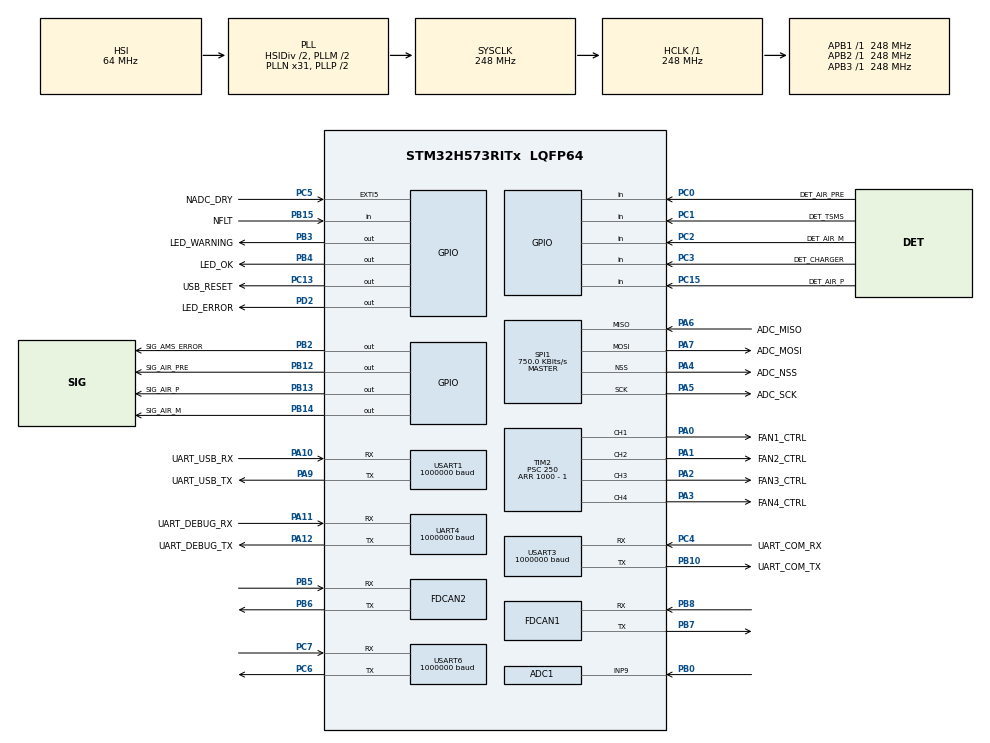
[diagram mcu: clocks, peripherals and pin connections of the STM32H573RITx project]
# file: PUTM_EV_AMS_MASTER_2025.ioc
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ADC1.Channel-0\#ChannelRegularConversion=ADC_CHANNEL_9
ADC1.ClockPrescaler=ADC_CLOCK_ASYNC_DIV16
ADC1.ContinuousConvMode=ENABLE
ADC1.MonitoredBy-0\#ChannelRegularConversion=__NULL
ADC1.NbrOfConversionFlag=1
ADC1.OffsetNumber-0\#ChannelRegularConversion=ADC_OFFSET_NONE
ADC1.Overrun=ADC_OVR_DATA_OVERWRITTEN
ADC1.Rank-0\#ChannelRegularConversion=1
ADC1.SamplingTime-0\#ChannelRegularConversion=ADC_SAMPLETIME_640CYCLES_5
ADC1.master=1
BOOTPATH.BootPathName=LEGACY
BOOTPATH.UserSelectedBootPath=LEGACY
CORTEX_M33_NS.userName=CORTEX_M33
FDCAN1.CalculateBaudRateNominal=500000
FDCAN1.CalculateTimeBitNominal=2000
FDCAN1.CalculateTimeQuantumNominal=32.25806451612903
FDCAN1.ClockDivider=FDCAN_CLOCK_DIV4
FDCAN1.DataPrescaler=8
FDCAN1.DataSyncJumpWidth=15
FDCAN1.DataTimeSeg1=15
FDCAN1.DataTimeSeg2=15
FDCAN1.Mode=FDCAN_MODE_NORMAL
FDCAN1.NominalPrescaler=2
FDCAN1.NominalSyncJumpWidth=2
FDCAN1.NominalTimeSeg1=59
FDCAN1.NominalTimeSeg2=2
FDCAN1.StdFiltersNbr=0
FDCAN2.CalculateBaudRateNominal=1000000
FDCAN2.CalculateTimeBitNominal=1000
FDCAN2.CalculateTimeQuantumNominal=16.129032258064516
FDCAN2.ClockDivider=FDCAN_CLOCK_DIV4
FDCAN2.DataPrescaler=2
FDCAN2.DataSyncJumpWidth=15
FDCAN2.DataTimeSeg1=15
FDCAN2.DataTimeSeg2=15
FDCAN2.Mode=FDCAN_MODE_NORMAL
FDCAN2.NominalPrescaler=1
FDCAN2.NominalSyncJumpWidth=15
FDCAN2.NominalTimeSeg1=46
FDCAN2.NominalTimeSeg2=15
FLASH.EDATA2size=7
FLASH.OB_EDATA2_active=true
FLASH.advanced_settings=false
GPDMA1.DATAHANDLING_GPDMACH2=NONE
GPDMA1.DESTDATAWIDTH_GPDMACH0=DMA_DEST_DATAWIDTH_WORD
GPDMA1.DESTDATAWIDTH_GPDMACH1=DMA_DEST_DATAWIDTH_WORD
GPDMA1.DESTINC_GPDMACH0=DMA_DINC_INCREMENTED
GPDMA1.DESTINC_GPDMACH2=DMA_DINC_INCREMENTED
GPDMA1.DESTINC_GPDMACH3=DMA_DINC_FIXED
GPDMA1.DIRECTION_GPDMACH1=DMA_MEMORY_TO_PERIPH
GPDMA1.DIRECTION_GPDMACH3=DMA_MEMORY_TO_PERIPH
GPDMA1.DIRECTION_GPDMACH4=DMA_MEMORY_TO_PERIPH
GPDMA1.IPHANDLE_GPDMACH0-SIMPLEREQUEST_GPDMACH0=__NULL
GPDMA1.IPHANDLE_GPDMACH1-SIMPLEREQUEST_GPDMACH1=__NULL
GPDMA1.IPHANDLE_GPDMACH2-SIMPLEREQUEST_GPDMACH2=__NULL
GPDMA1.IPHANDLE_GPDMACH3-SIMPLEREQUEST_GPDMACH3=__NULL
GPDMA1.IPHANDLE_GPDMACH4-SIMPLEREQUEST_GPDMACH4=__NULL
GPDMA1.REQUEST_GPDMACH0=GPDMA1_REQUEST_SPI1_RX
GPDMA1.REQUEST_GPDMACH1=GPDMA1_REQUEST_SPI1_TX
GPDMA1.REQUEST_GPDMACH2=GPDMA1_REQUEST_UART4_RX
GPDMA1.REQUEST_GPDMACH3=GPDMA1_REQUEST_UART4_TX
GPDMA1.REQUEST_GPDMACH4=GPDMA1_REQUEST_USART6_TX
GPDMA1.SRCDATAWIDTH_GPDMACH0=DMA_SRC_DATAWIDTH_WORD
GPDMA1.SRCDATAWIDTH_GPDMACH1=DMA_SRC_DATAWIDTH_WORD
GPDMA1.SRCINC_GPDMACH0=DMA_SINC_FIXED
GPDMA1.SRCINC_GPDMACH1=DMA_SINC_INCREMENTED
GPDMA1.SRCINC_GPDMACH3=DMA_SINC_INCREMENTED
GPDMA1.TRANSFERALLOCATEDPORTDEST_GPDMACH0=DMA_DEST_ALLOCATED_PORT1
GPDMA1.TRANSFERALLOCATEDPORTDEST_GPDMACH1=DMA_DEST_ALLOCATED_PORT0
GPDMA1.TRANSFERALLOCATEDPORTDEST_GPDMACH2=DMA_DEST_ALLOCATED_PORT1
GPDMA1.TRANSFERALLOCATEDPORTSRC_GPDMACH1=DMA_SRC_ALLOCATED_PORT1
GPDMA1.TRANSFERALLOCATEDPORTSRC_GPDMACH3=DMA_SRC_ALLOCATED_PORT1
GPDMA1.TRIGGERPOLARITY_GPDMACH2=DMA_TRIG_POLARITY_MASKED
GPDMA2.DESTINC_GPDMACH0=DMA_DINC_INCREMENTED
GPDMA2.DESTINC_GPDMACH2=DMA_DINC_INCREMENTED
GPDMA2.DIRECTION_GPDMACH1=DMA_MEMORY_TO_PERIPH
GPDMA2.DIRECTION_GPDMACH3=DMA_MEMORY_TO_PERIPH
GPDMA2.IPHANDLE_GPDMACH0-SIMPLEREQUEST_GPDMACH0=__NULL
GPDMA2.IPHANDLE_GPDMACH1-SIMPLEREQUEST_GPDMACH1=__NULL
GPDMA2.IPHANDLE_GPDMACH2-SIMPLEREQUEST_GPDMACH2=__NULL
GPDMA2.IPHANDLE_GPDMACH3-SIMPLEREQUEST_GPDMACH3=__NULL
GPDMA2.REQUEST_GPDMACH0=GPDMA2_REQUEST_USART1_RX
GPDMA2.REQUEST_GPDMACH1=GPDMA2_REQUEST_USART1_TX
GPDMA2.REQUEST_GPDMACH2=GPDMA2_REQUEST_USART3_RX
GPDMA2.REQUEST_GPDMACH3=GPDMA2_REQUEST_USART3_TX
GPDMA2.SRCINC_GPDMACH1=DMA_SINC_INCREMENTED
GPDMA2.SRCINC_GPDMACH3=DMA_SINC_INCREMENTED
GPDMA2.TRANSFERALLOCATEDPORTDEST_GPDMACH0=DMA_DEST_ALLOCATED_PORT1
GPDMA2.TRANSFERALLOCATEDPORTDEST_GPDMACH2=DMA_DEST_ALLOCATED_PORT1
GPDMA2.TRANSFERALLOCATEDPORTSRC_GPDMACH1=DMA_SRC_ALLOCATED_PORT1
GPDMA2.TRANSFERALLOCATEDPORTSRC_GPDMACH3=DMA_SRC_ALLOCATED_PORT1
Mcu.Family=STM32H5
Mcu.Name=STM32H573RITx
Mcu.Package=LQFP64
NVIC.FDCAN2_IT0_IRQn=true\:0\:0\:false\:false\:true\:false\:true\:true\:true
NVIC.FDCAN2_IT1_IRQn=true\:0\:0\:false\:false\:true\:false\:true\:true\:true
NVIC.GPDMA1_Channel0_IRQn=true\:0\:0\:false\:false\:true\:false\:true\:true\:true
NVIC.GPDMA1_Channel1_IRQn=true\:0\:0\:false\:false\:true\:false\:true\:true\:true
NVIC.GPDMA1_Channel2_IRQn=true\:0\:0\:false\:false\:true\:false\:false\:true\:true
NVIC.GPDMA1_Channel3_IRQn=true\:0\:0\:false\:false\:true\:false\:false\:true\:true
NVIC.GPDMA1_Channel4_IRQn=true\:0\:0\:false\:false\:true\:true\:false\:true\:true
NVIC.GPDMA2_Channel0_IRQn=true\:0\:0\:false\:false\:true\:true\:false\:true\:true
NVIC.GPDMA2_Channel1_IRQn=true\:0\:0\:false\:false\:true\:true\:false\:true\:true
NVIC.GPDMA2_Channel2_IRQn=true\:0\:0\:false\:false\:true\:true\:false\:true\:true
NVIC.GPDMA2_Channel3_IRQn=true\:0\:0\:false\:false\:true\:true\:false\:true\:true
NVIC.PriorityGroup=NVIC_PRIORITYGROUP_4
NVIC.SPI1_IRQn=true\:0\:0\:false\:false\:true\:false\:true\:true\:true
NVIC.TIM1_UP_IRQn=true\:15\:0\:false\:false\:true\:false\:false\:true\:true
NVIC.TimeBase=TIM1_UP_IRQn
NVIC.TimeBaseIP=TIM1
NVIC.UART4_IRQn=true\:0\:0\:false\:false\:true\:false\:true\:true\:true
NVIC.USART1_IRQn=true\:0\:0\:false\:false\:true\:false\:true\:true\:true
NVIC.USART3_IRQn=true\:0\:0\:false\:false\:true\:false\:true\:true\:true
NVIC.USART6_IRQn=true\:0\:0\:false\:false\:true\:false\:true\:true\:true
PA0.GPIO_Label=FAN1_CTRL
PA0.Signal=S_TIM2_CH1
PA1.GPIO_Label=FAN2_CTRL
PA1.Signal=S_TIM2_CH2
PA10.GPIO_Label=UART_USB_RX
PA10.Mode=Asynchronous
PA10.Signal=USART1_RX
PA11.GPIO_Label=UART_DEBUG_RX
PA11.Mode=Asynchronous
PA11.Signal=UART4_RX
PA12.GPIO_Label=UART_DEBUG_TX
PA12.Mode=Asynchronous
PA12.Signal=UART4_TX
PA13(JTMS/SWDIO).Mode=Serial_Wire
PA13(JTMS/SWDIO).Signal=DEBUG_JTMS-SWDIO
PA14(JTCK/SWCLK).Mode=Serial_Wire
PA14(JTCK/SWCLK).Signal=DEBUG_JTCK-SWCLK
PA2.GPIO_Label=FAN3_CTRL
PA2.Signal=S_TIM2_CH3
PA3.GPIO_Label=FAN4_CTRL
PA3.Signal=S_TIM2_CH4
PA4.GPIO_Label=ADC_NSS
PA4.Mode=NSS_Signal_Hard_Output
PA4.Signal=SPI1_NSS
PA5.GPIO_Label=ADC_SCK
PA5.Mode=Full_Duplex_Master
PA5.Signal=SPI1_SCK
PA6.GPIO_Label=ADC_MISO
PA6.Mode=Full_Duplex_Master
PA6.Signal=SPI1_MISO
PA7.GPIO_Label=ADC_MOSI
PA7.Mode=Full_Duplex_Master
PA7.Signal=SPI1_MOSI
PA9.GPIO_Label=UART_USB_TX
PA9.Mode=Asynchronous
PA9.Signal=USART1_TX
PB0.Signal=ADCx_INP9
PB10.GPIO_Label=UART_COM_TX
PB10.Mode=Asynchronous
PB10.Signal=USART3_TX
PB12.GPIO_Label=SIG_AIR_PRE
PB12.Signal=GPIO_Output
PB13.GPIO_Label=SIG_AIR_P
PB13.Signal=GPIO_Output
PB14.GPIO_Label=SIG_AIR_M
PB14.Signal=GPIO_Output
PB15.GPIO_Label=NFLT
PB15.Signal=GPIO_Input
PB2.GPIO_Label=SIG_AMS_ERROR
PB2.Signal=GPIO_Output
PB3(JTDO/TRACESWO).GPIO_Label=LED_WARNING
PB3(JTDO/TRACESWO).Signal=GPIO_Output
PB4(NJTRST).GPIO_Label=LED_OK
PB4(NJTRST).Signal=GPIO_Output
PB5.GPIO_Speed=GPIO_SPEED_FREQ_LOW
PB5.Mode=FDCAN_Activate
PB5.Signal=FDCAN2_RX
PB6.GPIO_Speed=GPIO_SPEED_FREQ_LOW
PB6.Mode=FDCAN_Activate
PB6.Signal=FDCAN2_TX
PB7.Mode=FDCAN_Activate
PB7.Signal=FDCAN1_TX
PB8.Mode=FDCAN_Activate
PB8.Signal=FDCAN1_RX
PC0.GPIO_Label=DET_AIR_PRE
PC0.GPIO_PuPd=GPIO_PULLUP
PC0.Signal=GPIO_Input
PC1.GPIO_Label=DET_TSMS
PC1.GPIO_PuPd=GPIO_PULLUP
PC1.Signal=GPIO_Input
PC13.GPIO_Label=USB_RESET
PC13.Signal=GPIO_Output
PC15-OSC32_OUT(OSC32_OUT).GPIO_Label=DET_AIR_P
PC15-OSC32_OUT(OSC32_OUT).GPIO_PuPd=GPIO_PULLUP
PC15-OSC32_OUT(OSC32_OUT).Signal=GPIO_Input
PC2.GPIO_Label=DET_AIR_M
PC2.GPIO_PuPd=GPIO_PULLUP
PC2.Signal=GPIO_Input
PC3.GPIO_Label=DET_CHARGER
PC3.GPIO_PuPd=GPIO_PULLUP
PC3.Signal=GPIO_Input
PC4.GPIO_Label=UART_COM_RX
PC4.Mode=Asynchronous
PC4.Signal=USART3_RX
PC5.GPIO_Label=NADC_DRY
PC5.Signal=GPXTI5
PC6.Mode=Asynchronous
PC6.Signal=USART6_TX
PC7.Mode=Asynchronous
PC7.Signal=USART6_RX
PD2.GPIO_Label=LED_ERROR
PD2.Signal=GPIO_Output
ProjectManager.HeapSize=0x2000
ProjectManager.StackSize=0x2000
ProjectManager.TargetToolchain=CMake
RCC.ADCCLockSelection=RCC_ADCDACCLKSOURCE_HSI
RCC.ADCFreq_Value=32000000
RCC.AHBFreq_Value=248000000
RCC.APB1Freq_Value=248000000
RCC.APB1TimFreq_Value=248000000
RCC.APB2Freq_Value=248000000
RCC.APB2TimFreq_Value=248000000
RCC.APB3Freq_Value=248000000
RCC.CSI_VALUE=4000000
RCC.CortexFreq_Value=248000000
RCC.EPOD_VALUE=32000000
RCC.FDCANClockSelection=RCC_FDCANCLKSOURCE_PLL1Q
RCC.HCLKFreq_Value=248000000
RCC.HSE_VALUE=50000000
RCC.HSI48_VALUE=48000000
RCC.HSI_VALUE=64000000
RCC.LSE_VALUE=32768
RCC.LSIRC_VALUE=32000
RCC.PLL2FRACN=0
RCC.PLL2M=2
RCC.PLL2N=24
RCC.PLL2P=64
RCC.PLL2Source=RCC_PLL2_SOURCE_HSI
RCC.PLL3FRACN=0
RCC.PLL3M=2
RCC.PLL3N=24
RCC.PLL3Q=8
RCC.PLL3Source=RCC_PLL3_SOURCE_HSI
RCC.PLLFRACN=0
RCC.PLLM=2
RCC.PLLN=31
RCC.PLLSourceVirtual=RCC_PLL1_SOURCE_HSI
RCC.SPI1CLockSelection=RCC_SPI1CLKSOURCE_PLL2P
RCC.SPI3CLockSelection=RCC_SPI3CLKSOURCE_PLL2P
RCC.SYSCLKFreq_VALUE=248000000
RCC.SYSCLKSource=RCC_SYSCLKSOURCE_PLLCLK
RCC.USBFreq_Value=48000000
RCC.VCOOutputFreq_Value=496000000
SH.ADCx_INP9.0=ADC1_INP9,IN9-Single-Ended
SH.S_TIM2_CH1.0=TIM2_CH1,PWM Generation1 CH1
SH.S_TIM2_CH2.0=TIM2_CH2,PWM Generation2 CH2
SH.S_TIM2_CH3.0=TIM2_CH3,PWM Generation3 CH3
SH.S_TIM2_CH4.0=TIM2_CH4,PWM Generation4 CH4
SPI1.BaudRatePrescaler=SPI_BAUDRATEPRESCALER_8
SPI1.CLKPhase=SPI_PHASE_2EDGE
SPI1.CalculateBaudRate=750.0 KBits/s
SPI1.DataSize=SPI_DATASIZE_24BIT
SPI1.Direction=SPI_DIRECTION_2LINES
SPI1.MasterSSIdleness=SPI_MASTER_SS_IDLENESS_04CYCLE
SPI1.Mode=SPI_MODE_MASTER
SPI1.TIMode=SPI_TIMODE_DISABLE
SPI1.VirtualNSS=VM_NSSHARD
SPI1.VirtualType=VM_MASTER
THREADX.TX_ENABLE_STACK_CHECKING=1
THREADX.TX_MINIMUM_STACK=1024
THREADX.TX_TIMER_TICKS_PER_SECOND=1000
TIM2.Channel-PWM\ Generation1\ CH1=TIM_CHANNEL_1
TIM2.Channel-PWM\ Generation2\ CH2=TIM_CHANNEL_2
TIM2.Channel-PWM\ Generation3\ CH3=TIM_CHANNEL_3
TIM2.Channel-PWM\ Generation4\ CH4=TIM_CHANNEL_4
TIM2.OCMode_PWM-PWM\ Generation1\ CH1=TIM_OCMODE_PWM1
TIM2.OCMode_PWM-PWM\ Generation2\ CH2=TIM_OCMODE_PWM1
TIM2.OCMode_PWM-PWM\ Generation3\ CH3=TIM_OCMODE_PWM1
TIM2.OCMode_PWM-PWM\ Generation4\ CH4=TIM_OCMODE_PWM1
TIM2.PeriodNoDither=1000 - 1
TIM2.Prescaler=250
UART4.BaudRate=1000000
UART4.ClockPrescaler=PRESCALER_DIV8
USART1.BaudRate=1000000
USART1.VirtualMode-Asynchronous=VM_ASYNC
USART3.BaudRate=1000000
USART3.ClockPrescaler=PRESCALER_DIV8
USART3.FIFOMode=FIFOMODE_DISABLE
USART3.VirtualMode-Asynchronous=VM_ASYNC
USART6.BaudRate=1000000
USART6.ClockPrescaler=PRESCALER_DIV8
USART6.Mode=MODE_TX
USART6.VirtualMode=VM_ASYNC
VP_BOOTPATH_VS_BOOTPATH.Mode=BP_Activate
VP_CORTEX_M33_NS_VS_Hclk.Mode=Hclk_Mode
VP_CRC_VS_CRC.Mode=CRC_Activate
VP_FLASH_SIG_Activate_FlashIP.Mode=Activate_FlashIP
VP_GPDMA1_VS_GPDMACH0.Mode=SIMPLEREQUEST_GPDMACH0
VP_GPDMA1_VS_GPDMACH1.Mode=SIMPLEREQUEST_GPDMACH1
VP_GPDMA1_VS_GPDMACH2.Mode=SIMPLEREQUEST_GPDMACH2
VP_GPDMA1_VS_GPDMACH3.Mode=SIMPLEREQUEST_GPDMACH3
VP_GPDMA1_VS_GPDMACH4.Mode=SIMPLEREQUEST_GPDMACH4
VP_GPDMA2_VS_GPDMACH0.Mode=SIMPLEREQUEST_GPDMACH0
VP_GPDMA2_VS_GPDMACH1.Mode=SIMPLEREQUEST_GPDMACH1
VP_GPDMA2_VS_GPDMACH2.Mode=SIMPLEREQUEST_GPDMACH2
VP_GPDMA2_VS_GPDMACH3.Mode=SIMPLEREQUEST_GPDMACH3
VP_ICACHE_VS_ICACHE.Mode=DefaultMode
VP_MEMORYMAP_VS_MEMORYMAP.Mode=CurAppReg
VP_PWR_VS_DBSignals.Mode=DisableDeadBatterySignals
VP_PWR_VS_LPOM.Mode=PowerOptimisation
VP_PWR_VS_SECSignals.Mode=Security/Privilege
VP_SYS_VS_tim1.Mode=TIM1
VP_THREADX_VS_RTOSJjThreadXJjCoreJjDefault.Mode=Core_Default
VP_THREADX_VS_RTOSJjThreadXJjPerformance_InfoJjDefault.Mode=Performance_Default
VP_THREADX_VS_RTOSJjThreadXJjTraceX_SupportJjDefault.Mode=TraceX_Support_Default
board=custom

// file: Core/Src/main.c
/* USER CODE BEGIN Header */
/**
  ******************************************************************************
  * @file           : main.c
  * @brief          : Main program body
  ******************************************************************************
  * @attention
  *
  * Copyright (c) 2025 STMicroelectronics.
  * All rights reserved.
  *
  * This software is licensed under terms that can be found in the LICENSE file
  * in the root directory of this software component.
  * If no LICENSE file comes with this software, it is provided AS-IS.
  *
  ******************************************************************************
  */
/* USER CODE END Header */
#include "app_threadx.h"
#include "main.h"
#include "adc.h"
#include "crc.h"
#include "fdcan.h"
#include "flash.h"
#include "gpdma.h"
#include "icache.h"
#include "spi.h"
#include "tim.h"
#include "usart.h"
#include "gpio.h"

void SystemClock_Config(void);

int main(void)
{

  /* MCU Configuration--------------------------------------------------------*/

  /* Reset of all peripherals, Initializes the Flash interface and the Systick. */
  HAL_Init();

  /* Configure the system clock */
  SystemClock_Config();

  /* Initialize all configured peripherals */
  MX_GPIO_Init();
  MX_GPDMA1_Init();
  MX_GPDMA2_Init();
  MX_FDCAN1_Init();
  MX_FDCAN2_Init();
  MX_SPI1_Init();
  MX_USART1_UART_Init();
  MX_ICACHE_Init();
  MX_TIM2_Init();
  MX_UART4_Init();
  MX_ADC1_Init();
  MX_USART3_UART_Init();
  MX_CRC_Init();
  MX_FLASH_Init();
  MX_USART6_UART_Init();

  MX_ThreadX_Init();

  /* We should never get here as control is now taken by the scheduler */

  /* Infinite loop */
  while (1)
  {

  }
}

void SystemClock_Config(void)
{
  RCC_OscInitTypeDef RCC_OscInitStruct = {0};
  RCC_ClkInitTypeDef RCC_ClkInitStruct = {0};

  /** Configure the main internal regulator output voltage
  */
  __HAL_PWR_VOLTAGESCALING_CONFIG(PWR_REGULATOR_VOLTAGE_SCALE0);

  while(!__HAL_PWR_GET_FLAG(PWR_FLAG_VOSRDY)) {}

  /** Initializes the RCC Oscillators according to the specified parameters
  * in the RCC_OscInitTypeDef structure.
  */
  RCC_OscInitStruct.OscillatorType = RCC_OSCILLATORTYPE_HSI;
  RCC_OscInitStruct.HSIState = RCC_HSI_ON;
  RCC_OscInitStruct.HSIDiv = RCC_HSI_DIV2;
  RCC_OscInitStruct.HSICalibrationValue = RCC_HSICALIBRATION_DEFAULT;
  RCC_OscInitStruct.PLL.PLLState = RCC_PLL_ON;
  RCC_OscInitStruct.PLL.PLLSource = RCC_PLL1_SOURCE_HSI;
  RCC_OscInitStruct.PLL.PLLM = 2;
  RCC_OscInitStruct.PLL.PLLN = 31;
  RCC_OscInitStruct.PLL.PLLP = 2;
  RCC_OscInitStruct.PLL.PLLQ = 2;
  RCC_OscInitStruct.PLL.PLLR = 2;
  RCC_OscInitStruct.PLL.PLLRGE = RCC_PLL1_VCIRANGE_3;
  RCC_OscInitStruct.PLL.PLLVCOSEL = RCC_PLL1_VCORANGE_WIDE;
  RCC_OscInitStruct.PLL.PLLFRACN = 0;
  if (HAL_RCC_OscConfig(&RCC_OscInitStruct) != HAL_OK)
  {
    Error_Handler();
  }

  /** Initializes the CPU, AHB and APB buses clocks
  */
  RCC_ClkInitStruct.ClockType = RCC_CLOCKTYPE_HCLK|RCC_CLOCKTYPE_SYSCLK
                              |RCC_CLOCKTYPE_PCLK1|RCC_CLOCKTYPE_PCLK2
                              |RCC_CLOCKTYPE_PCLK3;
  RCC_ClkInitStruct.SYSCLKSource = RCC_SYSCLKSOURCE_PLLCLK;
  RCC_ClkInitStruct.AHBCLKDivider = RCC_SYSCLK_DIV1;
  RCC_ClkInitStruct.APB1CLKDivider = RCC_HCLK_DIV1;
  RCC_ClkInitStruct.APB2CLKDivider = RCC_HCLK_DIV1;
  RCC_ClkInitStruct.APB3CLKDivider = RCC_HCLK_DIV1;

  if (HAL_RCC_ClockConfig(&RCC_ClkInitStruct, FLASH_LATENCY_5) != HAL_OK)
  {
    Error_Handler();
  }

  /** Configure the programming delay
  */
  __HAL_FLASH_SET_PROGRAM_DELAY(FLASH_PROGRAMMING_DELAY_2);
}

/* USER CODE BEGIN 4 */
int __io_putchar(int ch) {
  // Code to write character 'ch' on the UART
  while(!(USART1->ISR & USART_ISR_TXE));
  USART1->TDR = ch;
  return ch;  //  On success, the character written is returned.
  //  If a writing error occurs, EOF is returned and the error indicator (ferror) is set.
}
/* USER CODE END 4 */

void HAL_TIM_PeriodElapsedCallback(TIM_HandleTypeDef *htim)
{
  if (htim->Instance == TIM1)
  {
    HAL_IncTick();
  }
}

void Error_Handler(void)
{
  /* USER CODE BEGIN Error_Handler_Debug */
  /* User can add his own implementation to report the HAL error return state */

  /* Hard coded state */
  HAL_GPIO_WritePin(LED_OK_GPIO_Port, LED_OK_Pin, GPIO_PIN_SET);
  HAL_GPIO_WritePin(LED_WARNING_GPIO_Port, LED_WARNING_Pin, GPIO_PIN_SET);
  HAL_GPIO_WritePin(SIG_AMS_ERROR_GPIO_Port, SIG_AMS_ERROR_Pin, GPIO_PIN_RESET);
  HAL_GPIO_WritePin(LED_ERROR_GPIO_Port, LED_ERROR_Pin, GPIO_PIN_RESET);
  while (1)
  {

  }
  /* USER CODE END Error_Handler_Debug */
}
